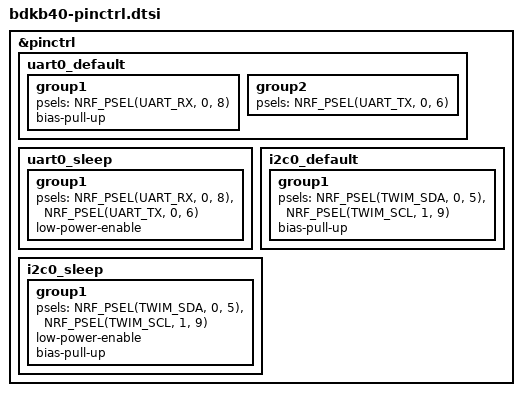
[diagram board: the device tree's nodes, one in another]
// This file was generated from a template. Edit it to match your keyboard.
// See https://docs.zephyrproject.org/4.1.0/hardware/porting/board_porting.html
// and https://docs.zephyrproject.org/4.1.0/hardware/pinctrl/index.html for
// more instructions.

#include <dt-bindings/pinctrl/nrf-pinctrl.h>

&pinctrl {
    uart0_default: uart0_default {
        group1 {
            psels = <NRF_PSEL(UART_RX, 0, 8)>;
            bias-pull-up;
        };
        group2 {
            psels = <NRF_PSEL(UART_TX, 0, 6)>;
        };
    };

    uart0_sleep: uart0_sleep {
        group1 {
            psels = <NRF_PSEL(UART_RX, 0, 8)>,
                    <NRF_PSEL(UART_TX, 0, 6)>;
            low-power-enable;
        };
    };

    i2c0_default: i2c0_default {
        group1 {
            psels = <NRF_PSEL(TWIM_SDA, 0, 5)>,
                    <NRF_PSEL(TWIM_SCL, 1, 9)>;
            bias-pull-up;
        };
    };

    i2c0_sleep: i2c0_sleep {
        group1 {
            psels = <NRF_PSEL(TWIM_SDA, 0, 5)>,
                    <NRF_PSEL(TWIM_SCL, 1, 9)>;
            low-power-enable;
            bias-pull-up;
        };
    };
};
